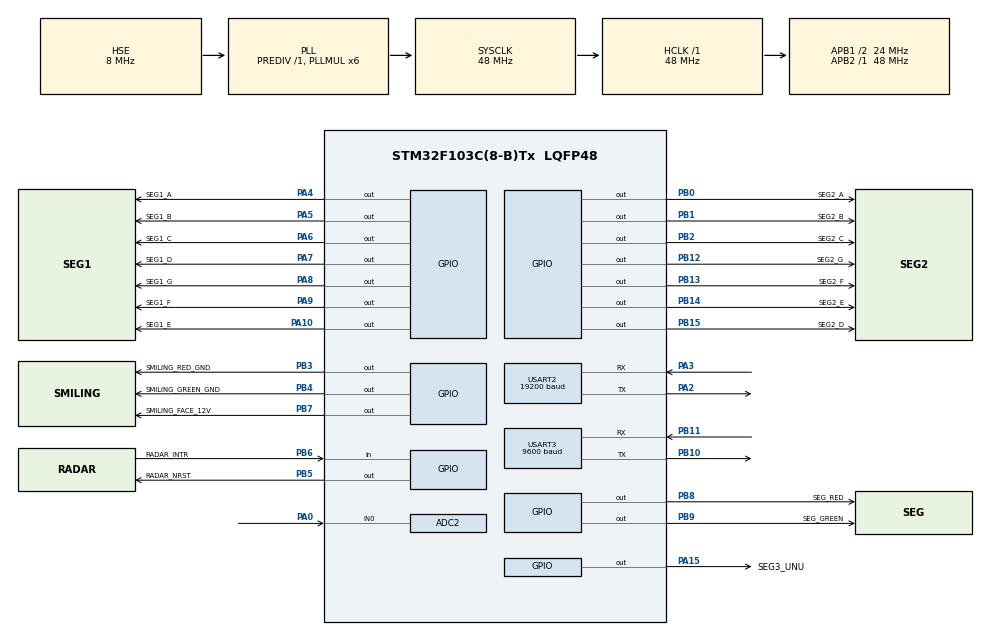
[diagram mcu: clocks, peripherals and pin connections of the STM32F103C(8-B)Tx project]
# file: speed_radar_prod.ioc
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ADC2.Channel-0\#ChannelRegularConversion=ADC_CHANNEL_0
ADC2.NbrOfConversionFlag=1
ADC2.Rank-0\#ChannelRegularConversion=1
ADC2.SamplingTime-0\#ChannelRegularConversion=ADC_SAMPLETIME_1CYCLE_5
Mcu.Family=STM32F1
Mcu.Name=STM32F103C(8-B)Tx
Mcu.Package=LQFP48
NVIC.PriorityGroup=NVIC_PRIORITYGROUP_4
NVIC.USART2_IRQn=true\:0\:0\:true\:false\:true\:true\:true\:true
NVIC.USART3_IRQn=true\:0\:0\:false\:false\:true\:true\:true\:true
PA0-WKUP.Signal=ADCx_IN0
PA1.Signal=ADCx_IN1
PA10.GPIO_Label=SEG1_E
PA10.Signal=GPIO_Output
PA13.Mode=Serial_Wire
PA13.Signal=SYS_JTMS-SWDIO
PA14.Mode=Serial_Wire
PA14.Signal=SYS_JTCK-SWCLK
PA15.GPIO_Label=SEG3_UNU
PA15.Signal=GPIO_Output
PA2.Mode=Asynchronous
PA2.Signal=USART2_TX
PA3.Mode=Asynchronous
PA3.Signal=USART2_RX
PA4.GPIO_Label=SEG1_A
PA4.Signal=GPIO_Output
PA5.GPIO_Label=SEG1_B
PA5.Signal=GPIO_Output
PA6.GPIO_Label=SEG1_C
PA6.Signal=GPIO_Output
PA7.GPIO_Label=SEG1_D
PA7.Signal=GPIO_Output
PA8.GPIO_Label=SEG1_G
PA8.Signal=GPIO_Output
PA9.GPIO_Label=SEG1_F
PA9.Signal=GPIO_Output
PB0.GPIO_Label=SEG2_A
PB0.GPIO_PuPd=GPIO_PULLUP
PB0.GPIO_Speed=GPIO_SPEED_FREQ_LOW
PB0.PinState=GPIO_PIN_SET
PB0.Signal=GPIO_Output
PB1.GPIO_Label=SEG2_B
PB1.Signal=GPIO_Output
PB10.Mode=Asynchronous
PB10.Signal=USART3_TX
PB11.Mode=Asynchronous
PB11.Signal=USART3_RX
PB12.GPIO_Label=SEG2_G
PB12.Signal=GPIO_Output
PB13.GPIO_Label=SEG2_F
PB13.Signal=GPIO_Output
PB14.GPIO_Label=SEG2_E
PB14.Signal=GPIO_Output
PB15.GPIO_Label=SEG2_D
PB15.Signal=GPIO_Output
PB2.GPIO_Label=SEG2_C
PB2.Signal=GPIO_Output
PB3.GPIO_Label=SMILING_RED_GND
PB3.Signal=GPIO_Output
PB4.GPIO_Label=SMILING_GREEN_GND
PB4.Signal=GPIO_Output
PB5.GPIO_Label=RADAR_NRST
PB5.Signal=GPIO_Output
PB6.GPIO_Label=RADAR_INTR
PB6.Signal=GPIO_Input
PB7.GPIO_Label=SMILING_FACE_12V
PB7.Signal=GPIO_Output
PB8.GPIO_Label=SEG_RED
PB8.Signal=GPIO_Output
PB9.GPIO_Label=SEG_GREEN
PB9.Signal=GPIO_Output
PC14-OSC32_IN.Mode=LSE-External-Oscillator
PC14-OSC32_IN.Signal=RCC_OSC32_IN
PC15-OSC32_OUT.Mode=LSE-External-Oscillator
PC15-OSC32_OUT.Signal=RCC_OSC32_OUT
PD0-OSC_IN.Mode=HSE-External-Oscillator
PD0-OSC_IN.Signal=RCC_OSC_IN
PD1-OSC_OUT.Mode=HSE-External-Oscillator
PD1-OSC_OUT.Signal=RCC_OSC_OUT
ProjectManager.HeapSize=0x200
ProjectManager.StackSize=0x400
ProjectManager.TargetToolchain=STM32CubeIDE
RCC.ADCPresc=RCC_ADCPCLK2_DIV4
RCC.AHBFreq_Value=48000000
RCC.APB1CLKDivider=RCC_HCLK_DIV2
RCC.APB1Freq_Value=24000000
RCC.APB1TimFreq_Value=48000000
RCC.APB2Freq_Value=48000000
RCC.APB2TimFreq_Value=48000000
RCC.HCLKFreq_Value=48000000
RCC.HSICalibrationValue=16
RCC.PLLMUL=RCC_PLL_MUL6
RCC.PLLSourceVirtual=RCC_PLLSOURCE_HSE
RCC.RTCClockSelection=RCC_RTCCLKSOURCE_LSE
RCC.SYSCLKFreq_VALUE=48000000
RCC.SYSCLKSource=RCC_SYSCLKSOURCE_PLLCLK
RCC.USBFreq_Value=48000000
SH.ADCx_IN0.0=ADC2_IN0,IN0
SH.ADCx_IN1.0=ADC2_IN1
TIM4.Period=1023
USART2.BaudRate=19200
USART2.VirtualMode=VM_ASYNC
USART3.BaudRate=9600
USART3.VirtualMode=VM_ASYNC
VP_RTC_VS_RTC_Activate.Mode=RTC_Enabled
VP_RTC_VS_RTC_Calendar.Mode=RTC_Calendar
VP_TIM4_VS_ClockSourceINT.Mode=Internal
board=custom

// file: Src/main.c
/* USER CODE BEGIN Header */
/**
  ******************************************************************************
  * @file           : main.c
  * @brief          : Main program body
  ******************************************************************************
  * @attention
  *
  * Copyright (c) 2024 STMicroelectronics.
  * All rights reserved.
  *
  * This software is licensed under terms that can be found in the LICENSE file
  * in the root directory of this software component.
  * If no LICENSE file comes with this software, it is provided AS-IS.
  *
  ******************************************************************************
  */
/* USER CODE END Header */
#include "main.h"
#include "adc.h"
#include "rtc.h"
#include "tim.h"
#include "usart.h"
#include "gpio.h"

/* USER CODE BEGIN Includes */
#include "speed_sign.h"
/* USER CODE END Includes */

void SystemClock_Config(void);
/* USER CODE BEGIN PFP */

#define PUTCHAR_PROTOTYPE int __io_putchar(int ch)

/* USER CODE END PFP */

int main(void)
{

  /* MCU Configuration--------------------------------------------------------*/

  /* Reset of all peripherals, Initializes the Flash interface and the Systick. */
  HAL_Init();

  /* Configure the system clock */
  SystemClock_Config();

  /* Initialize all configured peripherals */
  MX_GPIO_Init();
  MX_USART2_UART_Init();
  MX_RTC_Init();
  MX_USART3_UART_Init();
  MX_ADC2_Init();
  MX_TIM4_Init();
  /* USER CODE BEGIN 2 */
  speed_sign_init();
  /* USER CODE END 2 */

  /* Infinite loop */
  /* USER CODE BEGIN WHILE */
  while (1)
  {
	  speed_sign_loop();
    /* USER CODE END WHILE */

  }
}

void SystemClock_Config(void)
{
  RCC_OscInitTypeDef RCC_OscInitStruct = {0};
  RCC_ClkInitTypeDef RCC_ClkInitStruct = {0};
  RCC_PeriphCLKInitTypeDef PeriphClkInit = {0};

  /** Initializes the RCC Oscillators according to the specified parameters
  * in the RCC_OscInitTypeDef structure.
  */
  RCC_OscInitStruct.OscillatorType = RCC_OSCILLATORTYPE_HSE|RCC_OSCILLATORTYPE_LSE;
  RCC_OscInitStruct.HSEState = RCC_HSE_ON;
  RCC_OscInitStruct.HSEPredivValue = RCC_HSE_PREDIV_DIV1;
  RCC_OscInitStruct.LSEState = RCC_LSE_ON;
  RCC_OscInitStruct.HSIState = RCC_HSI_ON;
  RCC_OscInitStruct.PLL.PLLState = RCC_PLL_ON;
  RCC_OscInitStruct.PLL.PLLSource = RCC_PLLSOURCE_HSE;
  RCC_OscInitStruct.PLL.PLLMUL = RCC_PLL_MUL6;
  if (HAL_RCC_OscConfig(&RCC_OscInitStruct) != HAL_OK)
  {
    Error_Handler();
  }

  /** Initializes the CPU, AHB and APB buses clocks
  */
  RCC_ClkInitStruct.ClockType = RCC_CLOCKTYPE_HCLK|RCC_CLOCKTYPE_SYSCLK
                              |RCC_CLOCKTYPE_PCLK1|RCC_CLOCKTYPE_PCLK2;
  RCC_ClkInitStruct.SYSCLKSource = RCC_SYSCLKSOURCE_PLLCLK;
  RCC_ClkInitStruct.AHBCLKDivider = RCC_SYSCLK_DIV1;
  RCC_ClkInitStruct.APB1CLKDivider = RCC_HCLK_DIV2;
  RCC_ClkInitStruct.APB2CLKDivider = RCC_HCLK_DIV1;

  if (HAL_RCC_ClockConfig(&RCC_ClkInitStruct, FLASH_LATENCY_1) != HAL_OK)
  {
    Error_Handler();
  }
  PeriphClkInit.PeriphClockSelection = RCC_PERIPHCLK_RTC|RCC_PERIPHCLK_ADC;
  PeriphClkInit.RTCClockSelection = RCC_RTCCLKSOURCE_LSE;
  PeriphClkInit.AdcClockSelection = RCC_ADCPCLK2_DIV4;
  if (HAL_RCCEx_PeriphCLKConfig(&PeriphClkInit) != HAL_OK)
  {
    Error_Handler();
  }
}

/* USER CODE BEGIN 4 */
void delay(unsigned int interval_ms){
	HAL_Delay(interval_ms);
}

PUTCHAR_PROTOTYPE {
	/* Place your implementation of fputc here */
	/* e.g. write a character to the USART6 and Loop until the end of transmission */
#ifdef DEBUG
	HAL_UART_Transmit(&huart3, (uint8_t*) &ch, 1, 30);
#endif
	return ch;
}

/* USER CODE END 4 */

void Error_Handler(void)
{
  __disable_irq();
  while (1)
  {
  }
}
